VERSION ""

NS_ :

BS_:

BU_:

BO_ 49 ADC_Read_3: 2 Vector__XXX
 SG_ ADC_3_input : 0|12@1+ (10,0) [0|0] "mV" Vector__XXX

BO_ 48 ADC_Read_2: 2 Vector__XXX
 SG_ ADC_2_input : 0|12@1+ (1,0) [0|0] "mV" Vector__XXX

BO_ 32 ADC_Read_1: 2 Vector__XXX
 SG_ ADC_1_input : 0|12@1+ (1,0) [0|0] "mV" Vector__XXX

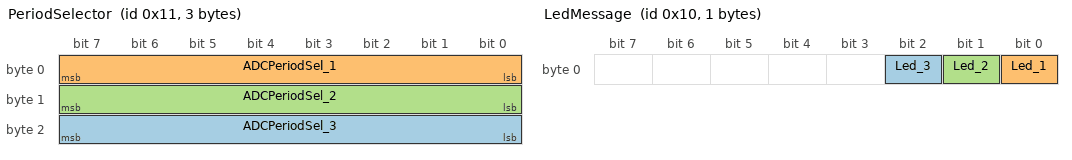
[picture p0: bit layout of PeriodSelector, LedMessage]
BO_ 17 PeriodSelector: 3 Vector__XXX
 SG_ ADCPeriodSel_3 : 16|8@1+ (100,0) [0|25] "ms" Vector__XXX
 SG_ ADCPeriodSel_1 : 0|8@1+ (100,0) [0|25] "ms" Vector__XXX
 SG_ ADCPeriodSel_2 : 8|8@1+ (100,0) [0|25] "ms" Vector__XXX

BO_ 16 LedMessage: 1 Vector__XXX
 SG_ Led_3 : 2|1@1+ (1,0) [0|0] "" Vector__XXX
 SG_ Led_1 : 0|1@1+ (1,0) [0|0] "" Vector__XXX
 SG_ Led_2 : 1|1@1+ (1,0) [0|0] "" Vector__XXX
